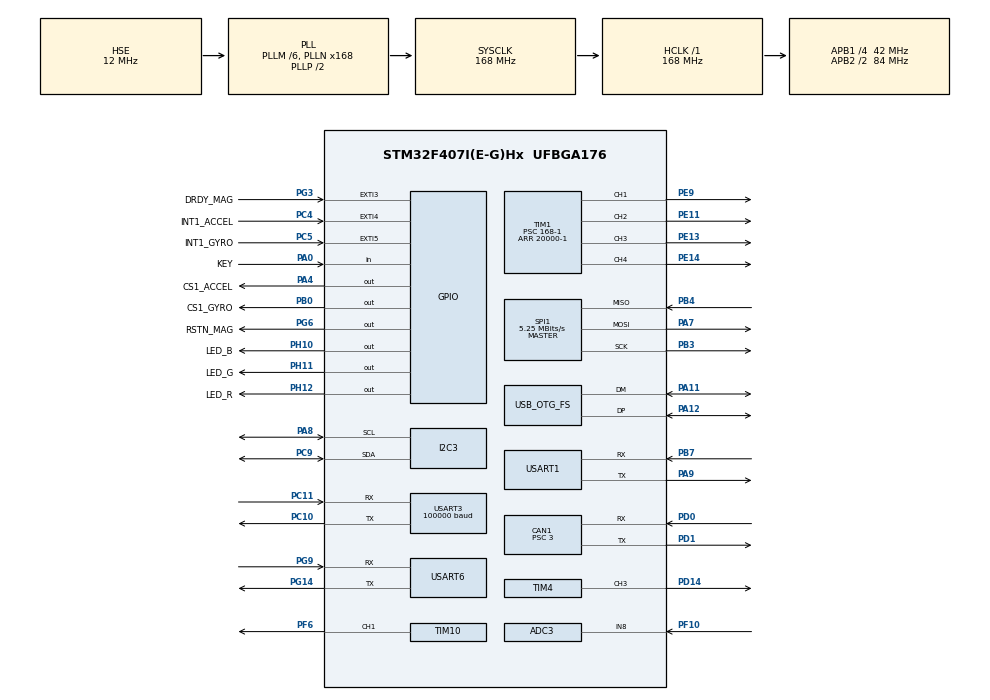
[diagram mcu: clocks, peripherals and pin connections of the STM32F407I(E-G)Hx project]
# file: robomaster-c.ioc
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ADC1.Channel-0\#ChannelRegularConversion=ADC_CHANNEL_VREFINT
ADC1.ClockPrescaler=ADC_CLOCK_SYNC_PCLK_DIV4
ADC1.NbrOfConversionFlag=1
ADC1.Rank-0\#ChannelRegularConversion=1
ADC1.SamplingTime-0\#ChannelRegularConversion=ADC_SAMPLETIME_3CYCLES
ADC1.master=1
ADC3.Channel-0\#ChannelRegularConversion=ADC_CHANNEL_8
ADC3.ClockPrescaler=ADC_CLOCK_SYNC_PCLK_DIV4
ADC3.NbrOfConversionFlag=1
ADC3.Rank-0\#ChannelRegularConversion=1
ADC3.SamplingTime-0\#ChannelRegularConversion=ADC_SAMPLETIME_3CYCLES
CAN1.BS1=CAN_BS1_10TQ
CAN1.BS2=CAN_BS2_3TQ
CAN1.CalculateBaudRate=1000000
CAN1.CalculateTimeBit=1000
CAN1.CalculateTimeQuantum=71.42857142857143
CAN1.Prescaler=3
Dma.Request0=USART3_RX
Dma.USART3_RX.0.Direction=DMA_PERIPH_TO_MEMORY
Dma.USART3_RX.0.FIFOMode=DMA_FIFOMODE_DISABLE
Dma.USART3_RX.0.Instance=DMA1_Stream1
Dma.USART3_RX.0.MemDataAlignment=DMA_MDATAALIGN_BYTE
Dma.USART3_RX.0.MemInc=DMA_MINC_ENABLE
Dma.USART3_RX.0.Mode=DMA_CIRCULAR
Dma.USART3_RX.0.PeriphDataAlignment=DMA_PDATAALIGN_BYTE
Dma.USART3_RX.0.PeriphInc=DMA_PINC_DISABLE
Dma.USART3_RX.0.Priority=DMA_PRIORITY_VERY_HIGH
FREERTOS.Events01=Imu_Event,Dynamic,NULL
FREERTOS.INCLUDE_pcTaskGetTaskName=1
FREERTOS.INCLUDE_xTaskGetHandle=1
FREERTOS.Tasks01=Led,8,128,Led_Entry,Default,NULL,Dynamic,NULL,NULL;Index,24,128,Index_Entry,As external,NULL,Dynamic,NULL,NULL;Rc,32,512,Rc_Entry,As external,NULL,Dynamic,NULL,NULL;Imu,48,512,Imu_Entry,As external,NULL,Dynamic,NULL,NULL
I2C3.I2C_Mode=I2C_Fast
Mcu.Family=STM32F4
Mcu.Name=STM32F407I(E-G)Hx
Mcu.Package=UFBGA176
NVIC.DMA1_Stream1_IRQn=true\:5\:0\:false\:false\:true\:true\:false\:true\:true
NVIC.EXTI3_IRQn=true\:5\:0\:false\:false\:true\:true\:true\:true\:true
NVIC.EXTI9_5_IRQn=true\:5\:0\:false\:false\:true\:true\:true\:true\:true
NVIC.OTG_FS_IRQn=true\:5\:0\:false\:false\:true\:true\:false\:true\:true
NVIC.PriorityGroup=NVIC_PRIORITYGROUP_4
NVIC.TIM6_DAC_IRQn=true\:15\:0\:false\:false\:true\:false\:false\:true\:true
NVIC.TimeBase=TIM6_DAC_IRQn
NVIC.TimeBaseIP=TIM6
NVIC.USART3_IRQn=true\:5\:0\:false\:false\:true\:true\:true\:true\:true
PA0-WKUP.GPIO_Label=KEY
PA0-WKUP.Signal=GPIO_Input
PA11.Mode=Device_Only
PA11.Signal=USB_OTG_FS_DM
PA12.GPIO_PuPd=GPIO_PULLUP
PA12.Mode=Device_Only
PA12.Signal=USB_OTG_FS_DP
PA13.Mode=Serial_Wire
PA13.Signal=SYS_JTMS-SWDIO
PA14.Mode=Serial_Wire
PA14.Signal=SYS_JTCK-SWCLK
PA4.GPIO_Label=CS1_ACCEL
PA4.GPIO_PuPd=GPIO_PULLUP
PA4.GPIO_Speed=GPIO_SPEED_FREQ_HIGH
PA4.PinState=GPIO_PIN_SET
PA4.Signal=GPIO_Output
PA7.Mode=Full_Duplex_Master
PA7.Signal=SPI1_MOSI
PA8.GPIO_Pu=GPIO_PULLUP
PA8.Mode=I2C
PA8.Signal=I2C3_SCL
PA9.Mode=Asynchronous
PA9.Signal=USART1_TX
PB0.GPIO_Label=CS1_GYRO
PB0.GPIO_PuPd=GPIO_PULLUP
PB0.GPIO_Speed=GPIO_SPEED_FREQ_HIGH
PB0.PinState=GPIO_PIN_SET
PB0.Signal=GPIO_Output
PB3.Mode=Full_Duplex_Master
PB3.Signal=SPI1_SCK
PB4.Mode=Full_Duplex_Master
PB4.Signal=SPI1_MISO
PB7.Mode=Asynchronous
PB7.Signal=USART1_RX
PC10.Mode=Asynchronous
PC10.Signal=USART3_TX
PC11.Mode=Asynchronous
PC11.Signal=USART3_RX
PC4.GPIO_Label=INT1_ACCEL
PC4.GPIO_ModeDefaultEXTI=GPIO_MODE_IT_FALLING
PC4.GPIO_PuPd=GPIO_PULLUP
PC4.Signal=GPXTI4
PC5.GPIO_Label=INT1_GYRO
PC5.GPIO_ModeDefaultEXTI=GPIO_MODE_IT_FALLING
PC5.GPIO_PuPd=GPIO_PULLUP
PC5.Signal=GPXTI5
PC9.GPIO_Pu=GPIO_PULLUP
PC9.Mode=I2C
PC9.Signal=I2C3_SDA
PD0.Mode=CAN_Activate
PD0.Signal=CAN1_RX
PD1.Mode=CAN_Activate
PD1.Signal=CAN1_TX
PD14.Signal=S_TIM4_CH3
PE11.GPIO_Speed=GPIO_SPEED_FREQ_VERY_HIGH
PE11.Signal=S_TIM1_CH2
PE13.GPIO_Speed=GPIO_SPEED_FREQ_VERY_HIGH
PE13.Signal=S_TIM1_CH3
PE14.GPIO_Speed=GPIO_SPEED_FREQ_VERY_HIGH
PE14.Signal=S_TIM1_CH4
PE9.GPIO_Speed=GPIO_SPEED_FREQ_VERY_HIGH
PE9.Signal=S_TIM1_CH1
PF10.Mode=IN8
PF10.Signal=ADC3_IN8
PF6.GPIO_PuPd=GPIO_PULLUP
PF6.GPIO_Speed=GPIO_SPEED_FREQ_VERY_HIGH
PF6.Signal=S_TIM10_CH1
PG14.Mode=Asynchronous
PG14.Signal=USART6_TX
PG3.GPIO_Label=DRDY_MAG
PG3.GPIO_ModeDefaultEXTI=GPIO_MODE_IT_FALLING
PG3.GPIO_PuPd=GPIO_PULLUP
PG3.Signal=GPXTI3
PG6.GPIO_Label=RSTN_MAG
PG6.GPIO_PuPd=GPIO_PULLUP
PG6.PinState=GPIO_PIN_SET
PG6.Signal=GPIO_Output
PG9.Mode=Asynchronous
PG9.Signal=USART6_RX
PH0-OSC_IN.Mode=HSE-External-Oscillator
PH0-OSC_IN.Signal=RCC_OSC_IN
PH1-OSC_OUT.Mode=HSE-External-Oscillator
PH1-OSC_OUT.Signal=RCC_OSC_OUT
PH10.GPIO_Label=LED_B
PH10.Signal=GPIO_Output
PH11.GPIO_Label=LED_G
PH11.Signal=GPIO_Output
PH12.GPIO_Label=LED_R
PH12.Signal=GPIO_Output
ProjectManager.HeapSize=0x200
ProjectManager.StackSize=0x400
ProjectManager.TargetToolchain=MDK-ARM V5.32
RCC.48MHZClocksFreq_Value=48000000
RCC.AHBFreq_Value=168000000
RCC.APB1CLKDivider=RCC_HCLK_DIV4
RCC.APB1Freq_Value=42000000
RCC.APB1TimFreq_Value=84000000
RCC.APB2CLKDivider=RCC_HCLK_DIV2
RCC.APB2Freq_Value=84000000
RCC.APB2TimFreq_Value=168000000
RCC.CortexFreq_Value=168000000
RCC.HCLKFreq_Value=168000000
RCC.HSE_VALUE=12000000
RCC.HSI_VALUE=16000000
RCC.LSE_VALUE=32768
RCC.PLLM=6
RCC.PLLN=168
RCC.PLLQ=7
RCC.SYSCLKFreq_VALUE=168000000
RCC.SYSCLKSource=RCC_SYSCLKSOURCE_PLLCLK
RCC.VCOOutputFreq_Value=336000000
SH.S_TIM10_CH1.0=TIM10_CH1,PWM Generation1 CH1
SH.S_TIM1_CH1.0=TIM1_CH1,PWM Generation1 CH1
SH.S_TIM1_CH2.0=TIM1_CH2,PWM Generation2 CH2
SH.S_TIM1_CH3.0=TIM1_CH3,PWM Generation3 CH3
SH.S_TIM1_CH4.0=TIM1_CH4,PWM Generation4 CH4
SH.S_TIM4_CH3.0=TIM4_CH3,PWM Generation3 CH3
SPI1.BaudRatePrescaler=SPI_BAUDRATEPRESCALER_16
SPI1.CLKPhase=SPI_PHASE_2EDGE
SPI1.CLKPolarity=SPI_POLARITY_HIGH
SPI1.CalculateBaudRate=5.25 MBits/s
SPI1.Direction=SPI_DIRECTION_2LINES
SPI1.Mode=SPI_MODE_MASTER
SPI1.VirtualType=VM_MASTER
TIM1.Channel-PWM\ Generation1\ CH1=TIM_CHANNEL_1
TIM1.Channel-PWM\ Generation2\ CH2=TIM_CHANNEL_2
TIM1.Channel-PWM\ Generation3\ CH3=TIM_CHANNEL_3
TIM1.Channel-PWM\ Generation4\ CH4=TIM_CHANNEL_4
TIM1.Period=20000-1
TIM1.Prescaler=168-1
TIM10.Channel=TIM_CHANNEL_1
TIM10.Period=5000-1
TIM4.Channel-PWM\ Generation3\ CH3=TIM_CHANNEL_3
TIM4.Period=21000-1
TIM4.Prescaler=0
USART1.VirtualMode=VM_ASYNC
USART3.BaudRate=100000
USART3.Parity=PARITY_EVEN
USART3.VirtualMode=VM_ASYNC
USART3.WordLength=WORDLENGTH_9B
USART6.VirtualMode=VM_ASYNC
USB_DEVICE.CLASS_NAME_FS=CDC
USB_DEVICE.VirtualMode-CDC_FS=Cdc
USB_DEVICE.VirtualModeFS=Cdc_FS
USB_OTG_FS.VirtualMode=Device_Only
VP_ADC1_Vref_Input.Mode=IN-Vrefint
VP_FREERTOS_VS_CMSIS_V2.Mode=CMSIS_V2
VP_SYS_VS_tim6.Mode=TIM6
VP_TIM10_VS_ClockSourceINT.Mode=Enable_Timer
VP_TIM1_VS_ClockSourceINT.Mode=Internal
VP_TIM4_VS_ClockSourceINT.Mode=Internal
VP_USB_DEVICE_VS_USB_DEVICE_CDC_FS.Mode=CDC_FS
board=custom

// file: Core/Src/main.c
/* USER CODE BEGIN Header */
/**
  ******************************************************************************
  * @file           : main.c
  * @brief          : Main program body
  ******************************************************************************
  * @attention
  *
  * Copyright (c) 2024 STMicroelectronics.
  * All rights reserved.
  *
  * This software is licensed under terms that can be found in the LICENSE file
  * in the root directory of this software component.
  * If no LICENSE file comes with this software, it is provided AS-IS.
  *
  ******************************************************************************
  */
/* USER CODE END Header */
#include "main.h"
#include "cmsis_os.h"
#include "adc.h"
#include "can.h"
#include "dma.h"
#include "i2c.h"
#include "spi.h"
#include "tim.h"
#include "usart.h"
#include "usb_device.h"
#include "gpio.h"

void SystemClock_Config(void);
void MX_FREERTOS_Init(void);

int main(void)
{

  /* MCU Configuration--------------------------------------------------------*/

  /* Reset of all peripherals, Initializes the Flash interface and the Systick. */
  HAL_Init();

  /* Configure the system clock */
  SystemClock_Config();

  /* Initialize all configured peripherals */
  MX_GPIO_Init();
  MX_DMA_Init();
  MX_USART1_UART_Init();
  MX_USART3_UART_Init();
  MX_ADC1_Init();
  MX_ADC3_Init();
  MX_CAN1_Init();
  MX_USART6_UART_Init();
  MX_I2C3_Init();
  MX_SPI1_Init();
  MX_TIM10_Init();
  MX_TIM1_Init();
  MX_TIM4_Init();

  /* Init scheduler */
  osKernelInitialize();

  /* Call init function for freertos objects (in cmsis_os2.c) */
  MX_FREERTOS_Init();

  /* Start scheduler */
  osKernelStart();

  /* We should never get here as control is now taken by the scheduler */

  /* Infinite loop */
  while (1)
  {

  }
}

void SystemClock_Config(void)
{
  RCC_OscInitTypeDef RCC_OscInitStruct = {0};
  RCC_ClkInitTypeDef RCC_ClkInitStruct = {0};

  /** Configure the main internal regulator output voltage
  */
  __HAL_RCC_PWR_CLK_ENABLE();
  __HAL_PWR_VOLTAGESCALING_CONFIG(PWR_REGULATOR_VOLTAGE_SCALE1);

  /** Initializes the RCC Oscillators according to the specified parameters
  * in the RCC_OscInitTypeDef structure.
  */
  RCC_OscInitStruct.OscillatorType = RCC_OSCILLATORTYPE_HSE;
  RCC_OscInitStruct.HSEState = RCC_HSE_ON;
  RCC_OscInitStruct.PLL.PLLState = RCC_PLL_ON;
  RCC_OscInitStruct.PLL.PLLSource = RCC_PLLSOURCE_HSE;
  RCC_OscInitStruct.PLL.PLLM = 6;
  RCC_OscInitStruct.PLL.PLLN = 168;
  RCC_OscInitStruct.PLL.PLLP = RCC_PLLP_DIV2;
  RCC_OscInitStruct.PLL.PLLQ = 7;
  if (HAL_RCC_OscConfig(&RCC_OscInitStruct) != HAL_OK)
  {
    Error_Handler();
  }

  /** Initializes the CPU, AHB and APB buses clocks
  */
  RCC_ClkInitStruct.ClockType = RCC_CLOCKTYPE_HCLK|RCC_CLOCKTYPE_SYSCLK
                              |RCC_CLOCKTYPE_PCLK1|RCC_CLOCKTYPE_PCLK2;
  RCC_ClkInitStruct.SYSCLKSource = RCC_SYSCLKSOURCE_PLLCLK;
  RCC_ClkInitStruct.AHBCLKDivider = RCC_SYSCLK_DIV1;
  RCC_ClkInitStruct.APB1CLKDivider = RCC_HCLK_DIV4;
  RCC_ClkInitStruct.APB2CLKDivider = RCC_HCLK_DIV2;

  if (HAL_RCC_ClockConfig(&RCC_ClkInitStruct, FLASH_LATENCY_5) != HAL_OK)
  {
    Error_Handler();
  }
}

void HAL_TIM_PeriodElapsedCallback(TIM_HandleTypeDef *htim)
{
  if (htim->Instance == TIM6) {
    HAL_IncTick();
  }
}

void Error_Handler(void)
{
  __disable_irq();
  while (1)
  {
  }
}

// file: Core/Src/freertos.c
/* USER CODE BEGIN Header */
/**
 ******************************************************************************
 * File Name          : freertos.c
 * Description        : Code for freertos applications
 ******************************************************************************
 * @attention
 *
 * Copyright (c) 2024 STMicroelectronics.
 * All rights reserved.
 *
 * This software is licensed under terms that can be found in the LICENSE file
 * in the root directory of this software component.
 * If no LICENSE file comes with this software, it is provided AS-IS.
 *
 ******************************************************************************
 */
/* USER CODE END Header */

#include "FreeRTOS.h"
#include "task.h"
#include "main.h"
#include "cmsis_os.h"

/* USER CODE BEGIN Includes */
#include "tp_thread.h"
#include "SEGGER_SYSVIEW.h"

/* USER CODE END Includes */

/* Definitions for Led */
osThreadId_t LedHandle;
const osThreadAttr_t Led_attributes = {
  .name = "Led",
  .stack_size = 128 * 4,
  .priority = (osPriority_t) osPriorityLow,
};
/* Definitions for Index */
osThreadId_t IndexHandle;
const osThreadAttr_t Index_attributes = {
  .name = "Index",
  .stack_size = 128 * 4,
  .priority = (osPriority_t) osPriorityNormal,
};
/* Definitions for Rc */
osThreadId_t RcHandle;
const osThreadAttr_t Rc_attributes = {
  .name = "Rc",
  .stack_size = 512 * 4,
  .priority = (osPriority_t) osPriorityAboveNormal,
};
/* Definitions for Imu */
osThreadId_t ImuHandle;
const osThreadAttr_t Imu_attributes = {
  .name = "Imu",
  .stack_size = 512 * 4,
  .priority = (osPriority_t) osPriorityRealtime,
};
/* Definitions for Imu_Event */
osEventFlagsId_t Imu_EventHandle;
const osEventFlagsAttr_t Imu_Event_attributes = {
  .name = "Imu_Event"
};

void Led_Entry(void *argument);
extern void Index_Entry(void *argument);
extern void Rc_Entry(void *argument);
extern void Imu_Entry(void *argument);

extern void MX_USB_DEVICE_Init(void);
void MX_FREERTOS_Init(void); /* (MISRA C 2004 rule 8.1) */

void MX_FREERTOS_Init(void) {
  /* USER CODE BEGIN Init */
  SEGGER_SYSVIEW_Conf();

  /* USER CODE END Init */

  /* Create the thread(s) */
  /* creation of Led */
  LedHandle = osThreadNew(Led_Entry, NULL, &Led_attributes);

  /* creation of Index */
  IndexHandle = osThreadNew(Index_Entry, NULL, &Index_attributes);

  /* creation of Rc */
  RcHandle = osThreadNew(Rc_Entry, NULL, &Rc_attributes);

  /* creation of Imu */
  ImuHandle = osThreadNew(Imu_Entry, NULL, &Imu_attributes);

  /* Create the event(s) */
  /* creation of Imu_Event */
  Imu_EventHandle = osEventFlagsNew(&Imu_Event_attributes);

}

void Led_Entry(void *argument)
{
  /* init code for USB_DEVICE */
  MX_USB_DEVICE_Init();
  /* USER CODE BEGIN Led_Entry */
  /* Infinite loop */
  for(;;)
  {
	LED_R_Toggle();
    osDelay(500);
  }
  /* USER CODE END Led_Entry */
}
